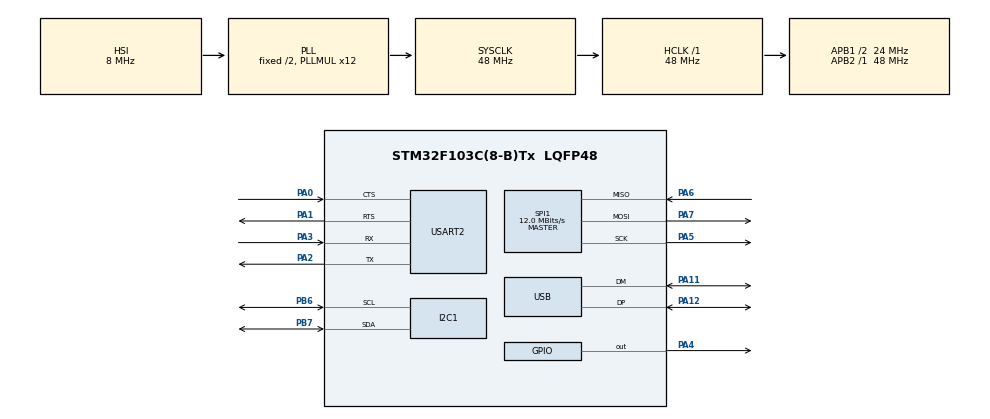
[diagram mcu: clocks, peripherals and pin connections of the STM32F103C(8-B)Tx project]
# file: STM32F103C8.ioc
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Dma.Request0=USART2_RX
Dma.Request1=USART2_TX
Dma.USART2_RX.0.Direction=DMA_PERIPH_TO_MEMORY
Dma.USART2_RX.0.Instance=DMA1_Channel6
Dma.USART2_RX.0.MemDataAlignment=DMA_MDATAALIGN_BYTE
Dma.USART2_RX.0.MemInc=DMA_MINC_ENABLE
Dma.USART2_RX.0.Mode=DMA_NORMAL
Dma.USART2_RX.0.PeriphDataAlignment=DMA_PDATAALIGN_BYTE
Dma.USART2_RX.0.PeriphInc=DMA_PINC_DISABLE
Dma.USART2_RX.0.Priority=DMA_PRIORITY_VERY_HIGH
Dma.USART2_TX.1.Direction=DMA_MEMORY_TO_PERIPH
Dma.USART2_TX.1.Instance=DMA1_Channel7
Dma.USART2_TX.1.MemDataAlignment=DMA_MDATAALIGN_BYTE
Dma.USART2_TX.1.MemInc=DMA_MINC_ENABLE
Dma.USART2_TX.1.Mode=DMA_NORMAL
Dma.USART2_TX.1.PeriphDataAlignment=DMA_PDATAALIGN_BYTE
Dma.USART2_TX.1.PeriphInc=DMA_PINC_DISABLE
Dma.USART2_TX.1.Priority=DMA_PRIORITY_LOW
Mcu.Family=STM32F1
Mcu.Name=STM32F103C(8-B)Tx
Mcu.Package=LQFP48
NVIC.DMA1_Channel6_IRQn=true\:0\:0\:false\:false\:true\:false\:true
NVIC.DMA1_Channel7_IRQn=true\:0\:0\:false\:false\:true\:false\:true
NVIC.PriorityGroup=NVIC_PRIORITYGROUP_4
NVIC.TIM4_IRQn=true\:0\:0\:true\:false\:true\:false\:true
NVIC.TimeBase=TIM4_IRQn
NVIC.TimeBaseIP=TIM4
NVIC.USART2_IRQn=true\:0\:0\:false\:false\:true\:true\:true
NVIC.USB_LP_CAN1_RX0_IRQn=true\:4\:0\:true\:false\:true\:false\:true
PA0-WKUP.Mode=CTS_RTS
PA0-WKUP.Signal=USART2_CTS
PA1.Mode=CTS_RTS
PA1.Signal=USART2_RTS
PA11.Mode=Device
PA11.Signal=USB_DM
PA12.Mode=Device
PA12.Signal=USB_DP
PA13.Mode=Serial_Wire
PA13.Signal=SYS_JTMS-SWDIO
PA14.Mode=Serial_Wire
PA14.Signal=SYS_JTCK-SWCLK
PA2.Mode=Asynchronous
PA2.Signal=USART2_TX
PA3.GPIO_PuPd=GPIO_PULLUP
PA3.Mode=Asynchronous
PA3.Signal=USART2_RX
PA4.GPIO_Speed=GPIO_SPEED_FREQ_HIGH
PA4.PinState=GPIO_PIN_SET
PA4.Signal=GPIO_Output
PA5.Mode=Full_Duplex_Master
PA5.Signal=SPI1_SCK
PA6.Mode=Full_Duplex_Master
PA6.Signal=SPI1_MISO
PA7.Mode=Full_Duplex_Master
PA7.Signal=SPI1_MOSI
PB6.Mode=I2C
PB6.Signal=I2C1_SCL
PB7.Mode=I2C
PB7.Signal=I2C1_SDA
ProjectManager.HeapSize=0x200
ProjectManager.StackSize=0x400
ProjectManager.TargetToolchain=STM32CubeIDE
RCC.AHBFreq_Value=48000000
RCC.APB1CLKDivider=RCC_HCLK_DIV2
RCC.APB1Freq_Value=24000000
RCC.APB1TimFreq_Value=48000000
RCC.APB2Freq_Value=48000000
RCC.APB2TimFreq_Value=48000000
RCC.HCLKFreq_Value=48000000
RCC.PLLMUL=RCC_PLL_MUL12
RCC.PLLSource=RCC_PLLSOURCE_HSI_DIV2
RCC.PLLSourceVirtual=RCC_PLLSOURCE_HSI_DIV2
RCC.SYSCLKFreq_VALUE=48000000
RCC.SYSCLKSource=RCC_SYSCLKSOURCE_PLLCLK
RCC.USBFreq_Value=48000000
SPI1.BaudRatePrescaler=SPI_BAUDRATEPRESCALER_4
SPI1.CalculateBaudRate=12.0 MBits/s
SPI1.Direction=SPI_DIRECTION_2LINES
SPI1.Mode=SPI_MODE_MASTER
SPI1.VirtualType=VM_MASTER
USART2.VirtualMode=VM_ASYNC
USB_DEVICE.CLASS_NAME_FS=MSC
USB_DEVICE.MANUFACTURER_STRING=HYH
USB_DEVICE.VID=0x483
USB_DEVICE.VirtualMode=Msc
USB_DEVICE.VirtualModeFS=Msc_FS
VP_SYS_VS_tim4.Mode=TIM4
VP_USB_DEVICE_VS_USB_DEVICE_MSC_FS.Mode=MSC_FS
board=custom

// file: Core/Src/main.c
/* USER CODE BEGIN Header */
/**
  ******************************************************************************
  * @file           : main.c
  * @brief          : Main program body
  ******************************************************************************
  * @attention
  *
  * <h2><center>&copy; Copyright (c) 2020 STMicroelectronics.
  * All rights reserved.</center></h2>
  *
  * This software component is licensed by ST under BSD 3-Clause license,
  * the "License"; You may not use this file except in compliance with the
  * License. You may obtain a copy of the License at:
  *                        opensource.org/licenses/BSD-3-Clause
  *
  ******************************************************************************
  */
/* USER CODE END Header */

#include "main.h"
#include "usb_device.h"

/* USER CODE BEGIN Includes */
#include "VirtualFat.h"
/* USER CODE END Includes */

I2C_HandleTypeDef hi2c1;

SPI_HandleTypeDef hspi1;

UART_HandleTypeDef huart2;
DMA_HandleTypeDef hdma_usart2_rx;
DMA_HandleTypeDef hdma_usart2_tx;

void SystemClock_Config(void);
static void MX_GPIO_Init(void);
static void MX_DMA_Init(void);
static void MX_I2C1_Init(void);
static void MX_SPI1_Init(void);
static void MX_USART2_UART_Init(void);

int main(void)
{
  /* USER CODE BEGIN 1 */
	{//复位时断�??USB连接,再重新连接USB
		{
		  GPIO_InitTypeDef GPIO_InitStruct = {0};

		  /* GPIO Ports Clock Enable */
		  __HAL_RCC_GPIOA_CLK_ENABLE();

		  /*Configure GPIO pin Output Level */
		  HAL_GPIO_WritePin(GPIOA, GPIO_PIN_11|GPIO_PIN_12, GPIO_PIN_RESET);

		  /*Configure GPIO pins : PA11 PA12 */
		  GPIO_InitStruct.Pin = GPIO_PIN_11|GPIO_PIN_12;
		  GPIO_InitStruct.Mode = GPIO_MODE_OUTPUT_PP;
		  GPIO_InitStruct.Pull = GPIO_PULLDOWN;
		  GPIO_InitStruct.Speed = GPIO_SPEED_FREQ_LOW;
		  HAL_GPIO_Init(GPIOA, &GPIO_InitStruct);

		  /*Configure GPIO pin Output Level */
		  HAL_GPIO_WritePin(GPIOA, GPIO_PIN_11|GPIO_PIN_12, GPIO_PIN_RESET);

		}
		{//延时�??
			uint32_t count=48000000/100;
			while(count--);
		}
	}
  /* USER CODE END 1 */

  /* MCU Configuration--------------------------------------------------------*/

  /* Reset of all peripherals, Initializes the Flash interface and the Systick. */
  HAL_Init();

  /* Configure the system clock */
  SystemClock_Config();

  /* Initialize all configured peripherals */
  MX_GPIO_Init();
  MX_DMA_Init();
  MX_I2C1_Init();
  MX_SPI1_Init();
  MX_USART2_UART_Init();
  MX_USB_DEVICE_Init();

  /* Infinite loop */
  while (1)
  {

  }
}

void SystemClock_Config(void)
{
  RCC_OscInitTypeDef RCC_OscInitStruct = {0};
  RCC_ClkInitTypeDef RCC_ClkInitStruct = {0};
  RCC_PeriphCLKInitTypeDef PeriphClkInit = {0};

  /** Initializes the CPU, AHB and APB busses clocks
  */
  RCC_OscInitStruct.OscillatorType = RCC_OSCILLATORTYPE_HSI;
  RCC_OscInitStruct.HSIState = RCC_HSI_ON;
  RCC_OscInitStruct.HSICalibrationValue = RCC_HSICALIBRATION_DEFAULT;
  RCC_OscInitStruct.PLL.PLLState = RCC_PLL_ON;
  RCC_OscInitStruct.PLL.PLLSource = RCC_PLLSOURCE_HSI_DIV2;
  RCC_OscInitStruct.PLL.PLLMUL = RCC_PLL_MUL12;
  if (HAL_RCC_OscConfig(&RCC_OscInitStruct) != HAL_OK)
  {
    Error_Handler();
  }
  /** Initializes the CPU, AHB and APB busses clocks
  */
  RCC_ClkInitStruct.ClockType = RCC_CLOCKTYPE_HCLK|RCC_CLOCKTYPE_SYSCLK
                              |RCC_CLOCKTYPE_PCLK1|RCC_CLOCKTYPE_PCLK2;
  RCC_ClkInitStruct.SYSCLKSource = RCC_SYSCLKSOURCE_PLLCLK;
  RCC_ClkInitStruct.AHBCLKDivider = RCC_SYSCLK_DIV1;
  RCC_ClkInitStruct.APB1CLKDivider = RCC_HCLK_DIV2;
  RCC_ClkInitStruct.APB2CLKDivider = RCC_HCLK_DIV1;

  if (HAL_RCC_ClockConfig(&RCC_ClkInitStruct, FLASH_LATENCY_1) != HAL_OK)
  {
    Error_Handler();
  }
  PeriphClkInit.PeriphClockSelection = RCC_PERIPHCLK_USB;
  PeriphClkInit.UsbClockSelection = RCC_USBCLKSOURCE_PLL;
  if (HAL_RCCEx_PeriphCLKConfig(&PeriphClkInit) != HAL_OK)
  {
    Error_Handler();
  }
}

static void MX_I2C1_Init(void)
{

  /* USER CODE BEGIN I2C1_Init 1 */
  __HAL_RCC_I2C1_CLK_ENABLE();
  /* USER CODE END I2C1_Init 1 */
  hi2c1.Instance = I2C1;
  hi2c1.Init.ClockSpeed = 100000;
  hi2c1.Init.DutyCycle = I2C_DUTYCYCLE_2;
  hi2c1.Init.OwnAddress1 = 0;
  hi2c1.Init.AddressingMode = I2C_ADDRESSINGMODE_7BIT;
  hi2c1.Init.DualAddressMode = I2C_DUALADDRESS_DISABLE;
  hi2c1.Init.OwnAddress2 = 0;
  hi2c1.Init.GeneralCallMode = I2C_GENERALCALL_DISABLE;
  hi2c1.Init.NoStretchMode = I2C_NOSTRETCH_DISABLE;
  if (HAL_I2C_Init(&hi2c1) != HAL_OK)
  {
    Error_Handler();
  }

}

static void MX_SPI1_Init(void)
{

  /* SPI1 parameter configuration*/
  hspi1.Instance = SPI1;
  hspi1.Init.Mode = SPI_MODE_MASTER;
  hspi1.Init.Direction = SPI_DIRECTION_2LINES;
  hspi1.Init.DataSize = SPI_DATASIZE_8BIT;
  hspi1.Init.CLKPolarity = SPI_POLARITY_LOW;
  hspi1.Init.CLKPhase = SPI_PHASE_1EDGE;
  hspi1.Init.NSS = SPI_NSS_SOFT;
  hspi1.Init.BaudRatePrescaler = SPI_BAUDRATEPRESCALER_4;
  hspi1.Init.FirstBit = SPI_FIRSTBIT_MSB;
  hspi1.Init.TIMode = SPI_TIMODE_DISABLE;
  hspi1.Init.CRCCalculation = SPI_CRCCALCULATION_DISABLE;
  hspi1.Init.CRCPolynomial = 10;
  if (HAL_SPI_Init(&hspi1) != HAL_OK)
  {
    Error_Handler();
  }

}

static void MX_USART2_UART_Init(void)
{

  huart2.Instance = USART2;
  huart2.Init.BaudRate = 115200;
  huart2.Init.WordLength = UART_WORDLENGTH_8B;
  huart2.Init.StopBits = UART_STOPBITS_1;
  huart2.Init.Parity = UART_PARITY_NONE;
  huart2.Init.Mode = UART_MODE_TX_RX;
  huart2.Init.HwFlowCtl = UART_HWCONTROL_RTS_CTS;
  huart2.Init.OverSampling = UART_OVERSAMPLING_16;
  if (HAL_UART_Init(&huart2) != HAL_OK)
  {
    Error_Handler();
  }

}

static void MX_DMA_Init(void)
{

  /* DMA controller clock enable */
  __HAL_RCC_DMA1_CLK_ENABLE();

  /* DMA interrupt init */
  /* DMA1_Channel6_IRQn interrupt configuration */
  HAL_NVIC_SetPriority(DMA1_Channel6_IRQn, 0, 0);
  HAL_NVIC_EnableIRQ(DMA1_Channel6_IRQn);
  /* DMA1_Channel7_IRQn interrupt configuration */
  HAL_NVIC_SetPriority(DMA1_Channel7_IRQn, 0, 0);
  HAL_NVIC_EnableIRQ(DMA1_Channel7_IRQn);

}

static void MX_GPIO_Init(void)
{
  GPIO_InitTypeDef GPIO_InitStruct = {0};

  /* GPIO Ports Clock Enable */
  __HAL_RCC_GPIOA_CLK_ENABLE();
  __HAL_RCC_GPIOB_CLK_ENABLE();

  /*Configure GPIO pin Output Level */
  HAL_GPIO_WritePin(GPIOA, GPIO_PIN_4, GPIO_PIN_SET);

  /*Configure GPIO pin : PA4 */
  GPIO_InitStruct.Pin = GPIO_PIN_4;
  GPIO_InitStruct.Mode = GPIO_MODE_OUTPUT_PP;
  GPIO_InitStruct.Pull = GPIO_NOPULL;
  GPIO_InitStruct.Speed = GPIO_SPEED_FREQ_HIGH;
  HAL_GPIO_Init(GPIOA, &GPIO_InitStruct);

}

 /**
  * @brief  Period elapsed callback in non blocking mode
  * @note   This function is called  when TIM4 interrupt took place, inside
  * HAL_TIM_IRQHandler(). It makes a direct call to HAL_IncTick() to increment
  * a global variable "uwTick" used as application time base.
  * @param  htim : TIM handle
  * @retval None
  */
void HAL_TIM_PeriodElapsedCallback(TIM_HandleTypeDef *htim)
{
  if (htim->Instance == TIM4) {
    HAL_IncTick();
  }
}

void Error_Handler(void)
{
}

/************************ (C) COPYRIGHT STMicroelectronics *****END OF FILE****/
